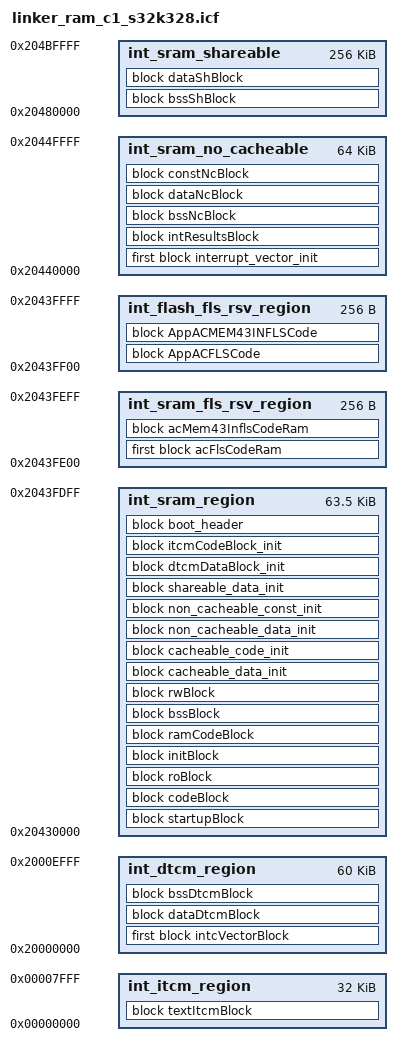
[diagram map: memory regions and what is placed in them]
/*==================================================================================================
*   Project              : RTD AUTOSAR 4.7
*   Platform             : CORTEXM
*   Peripheral           : 
*   Dependencies         : none
*
*   Autosar Version      : 4.7.0
*   Autosar Revision     : ASR_REL_4_7_REV_0000
*   Autosar Conf.Variant :
*   SW Version           : 5.0.0
*   Build Version        : S32K3_RTD_5_0_0_D2408_ASR_REL_4_7_REV_0000_20241002
*
*   Copyright 2020 - 2024 NXP
*
*   NXP Confidential and Proprietary. This software is owned or controlled by NXP and may only be 
*   used strictly in accordance with the applicable license terms.  By expressly 
*   accepting such terms or by downloading, installing, activating and/or otherwise 
*   using the software, you are agreeing that you have read, and that you agree to 
*   comply with and are bound by, such license terms.  If you do not agree to be 
*   bound by the applicable license terms, then you may not retain, install,
*   activate or otherwise use the software.
==================================================================================================*/
/*
* IAR Linker Command File:
* Target device: This linker is demo and it is using for device S32K328 only. It is not part of the production code deliverables.
* Target core: ARM cortex M7
* Linker support for application running on M7_1 core1 only. It need to align with MPU default setup in core_specific.h and system.c as well.
* Memory setting: Local ram of M7_1 (sram)
*/

/*
* IAR Linker Command File:
* 0x00000000    0x00007FFF  32768   ITCM_0
* 0x00000000    0x00007FFF  32768   ITCM_2
* 0x20000000    0x2000FFFF  65536   DTCM_0
* 0x20000000    0x2000FFFF  65536   DTCM_2
* 0x00400000    0x00BFFFFF  8388608 Program Flash
* 0x10000000    0x1001FFFF  131072  Data Flash
* 0x20400000    0x2043FFFF  262144  SRAM_0
* 0x20440000    0x2047FFFF  262144  SRAM_1
* 0x20480000    0x204BFFFF  262144  SRAM_2
* Last 176 KB of CODE_FLASH reserved by HSE Firmware
*/

define symbol int_itcm_start                  = 0x00000000;
define symbol int_itcm_size                   = 0x00008000;    /* 32KB */

define symbol int_dtcm_start                  = 0x20000000;
define symbol int_dtcm_size                   = 0x0000F000;    /* 60KB */

define symbol int_stack_dtcm_start            = 0x2000F000;
define symbol int_stack_dtcm_size             = 0x00001000;     /* 4KB */

define symbol int_sram_c0_start               = 0x20400000;
define symbol int_sram_c0_size                = 0x0001FE00;    /* 128KB. include fls_rsv_c0 */

define symbol int_sram_fls_rsv_c0_start       = 0x2041FE00;
define symbol int_sram_fls_rsv_c0_size        = 0x00000100;    /* 256 byte */

define symbol int_flash_fls_rsv_c0_start      = 0x2041FF00;
define symbol int_flash_fls_rsv_c0_size       = 0x00000100;    /* 256 byte */

define symbol int_sram_no_cacheable_c0_start  = 0x20420000;
define symbol int_sram_no_cacheable_c0_size   = 0x00010000;    /* 64KB, needs to include int_results */

define symbol ram_end_c0                      = 0x20430000;

define symbol int_sram_c1_start               = 0x20430000;
define symbol int_sram_c1_size                = 0x0000FE00;    /* 64KB. include int_sram_fls_rsv_c1 */

define symbol int_sram_fls_rsv_c1_start       = 0x2043FE00;
define symbol int_sram_fls_rsv_c1_size        = 0x00000100;    /* 256 byte for flash access code ram */

define symbol int_flash_fls_rsv_c1_start      = 0x2043FF00;
define symbol int_flash_fls_rsv_c1_size       = 0x00000100;    /* 256 byte for flash access code ram */

define symbol int_sram_no_cacheable_c1_start  = 0x20440000;
define symbol int_sram_no_cacheable_c1_size   = 0x00010000;    /* 64KB, needs to include int_results */

define symbol ram_end_c1                      = 0x20450000;

define symbol int_sram_c2_start               = 0x20450000;
define symbol int_sram_c2_size                = 0x0000FF00;    /* 64KB, include int_sram_fls_rsv_c2 */

define symbol int_sram_fls_rsv_c2_start       = 0x2045FE00;
define symbol int_sram_fls_rsv_c2_size        = 0x00000100;    /* 256 byte for flash access code ram */

define symbol int_flash_fls_rsv_c2_start      = 0x2045FF00;    /* 256 byte for flash access code ram */
define symbol int_flash_fls_rsv_c2_size       = 0x00000100;    /* 256 byte for flash access code ram */

define symbol int_sram_no_cacheable_c2_start  = 0x20460000;
define symbol int_sram_no_cacheable_c2_size   = 0x00020000;    /* 128KB, needs to include int_results  */

define symbol ram_end_c2                      = 0x20480000;

define symbol int_sram_shareable_start        = 0x20480000;
define symbol int_sram_shareable_size         = 0x00040000;    /* 256KB */

define symbol ram_rsvd2                       = 0x204C0000;

define exported symbol __Stack_dtcm_end      = int_stack_dtcm_start;
define exported symbol __Stack_dtcm_start    = int_stack_dtcm_start + int_stack_dtcm_size;

define exported symbol __RAM_INIT                    = 0;
define exported symbol __INT_SRAM_START              = int_sram_c1_start;
define exported symbol __INT_SRAM_END                = ram_end_c1;
define exported symbol __INT_SRAM_SHARE_START        = int_sram_shareable_start;
define exported symbol __INT_SRAM_SHARE_END          = int_sram_shareable_start + int_sram_shareable_size;
define exported symbol __ITCM_INIT                   = 1;
define exported symbol __INT_ITCM_START              = int_itcm_start;
define exported symbol __INT_ITCM_END                = int_itcm_start + int_itcm_size;
define exported symbol __DTCM_INIT                   = 1;
define exported symbol __INT_DTCM_START              = int_dtcm_start;
define exported symbol __INT_DTCM_END                = int_dtcm_start + int_dtcm_size + int_stack_dtcm_size;
define exported symbol __RAM_NO_CACHEABLE_START      = int_sram_no_cacheable_c1_start;

/* Fls module access code support */
define exported symbol int_ac_fls_code_rom_size = 0x80;
define exported symbol int_acmem_43_infls_code_rom_size = 0x80;
define exported symbol int_ac_fls_code_ram_size = 0x80;
define exported symbol int_acmem_43_infls_code_ram_size = 0x80;

define exported symbol Fls_ACEraseRomStart  = int_flash_fls_rsv_c1_start;
define exported symbol Fls_ACEraseRomEnd    = int_flash_fls_rsv_c1_start + int_ac_fls_code_rom_size;
define exported symbol Fls_ACEraseSize      = int_ac_fls_code_rom_size/4; /* Copy 4 bytes at a time*/

define exported symbol Fls_ACWriteRomStart  = int_flash_fls_rsv_c1_start;
define exported symbol Fls_ACWriteRomEnd    = int_flash_fls_rsv_c1_start + int_ac_fls_code_rom_size;
define exported symbol Fls_ACWriteSize      = int_ac_fls_code_rom_size/4; /* Copy 4 bytes at a time*/

define exported symbol _ERASE_FUNC_ADDRESS_ = int_sram_fls_rsv_c1_start;
define exported symbol _WRITE_FUNC_ADDRESS_ = int_sram_fls_rsv_c1_start;

define exported symbol Mem_43_INFLS_ACEraseRomStart  = int_flash_fls_rsv_c1_start + int_ac_fls_code_rom_size;
define exported symbol Mem_43_INFLS_ACEraseRomEnd    = int_flash_fls_rsv_c1_start + int_ac_fls_code_rom_size + int_acmem_43_infls_code_rom_size;
define exported symbol Mem_43_INFLS_ACEraseSize      = int_acmem_43_infls_code_rom_size/4; /* Copy 4 bytes at a time*/ 

define exported symbol Mem_43_INFLS_ACWriteRomStart  = int_flash_fls_rsv_c1_start + int_ac_fls_code_rom_size;
define exported symbol Mem_43_INFLS_ACWriteRomEnd    = int_flash_fls_rsv_c1_start + int_ac_fls_code_rom_size + int_acmem_43_infls_code_rom_size;
define exported symbol Mem_43_INFLS_ACWriteSize      = int_acmem_43_infls_code_rom_size/4; /* Copy 4 bytes at a time*/ 

define exported symbol _MEM_43_INFLS_ERASE_FUNC_ADDRESS_ = int_sram_fls_rsv_c1_start + int_ac_fls_code_ram_size;
define exported symbol _MEM_43_INFLS_WRITE_FUNC_ADDRESS_ = int_sram_fls_rsv_c1_start + int_ac_fls_code_ram_size;

define memory mem with size = 4G;

define region int_sram_region         = mem:[from int_sram_c1_start size int_sram_c1_size];
define region int_sram_no_cacheable   = mem:[from int_sram_no_cacheable_c1_start size int_sram_no_cacheable_c1_size];
define region int_sram_shareable      = mem:[from int_sram_shareable_start size int_sram_shareable_size];
define region int_itcm_region         = mem:[from int_itcm_start size int_itcm_size];
define region int_dtcm_region         = mem:[from int_dtcm_start size int_dtcm_size];
define region int_flash_fls_rsv_region = mem:[from int_flash_fls_rsv_c1_start size int_flash_fls_rsv_c1_size];
define region int_sram_fls_rsv_region  = mem:[from int_sram_fls_rsv_c1_start size int_sram_fls_rsv_c1_size];

initialize manually {
                    section .intvec,
                    section .dtcm_data,
                    section .itcm_text
                    };

do not initialize {
                    section .data,
                    section .mcal_data,
                    section .mcal_data_no_cacheable,
                    section .mcal_shared_data,
                    section .dtcm_data,
                    section .itcm_text,
                    section .bss,
                    section .mcal_bss,
                    section .mcal_bss_no_cacheable,
                    section .mcal_const_no_cacheable,
                    section .mcal_shared_bss,
                    section .dtcm_bss
                  };

/* Internal SRAM */
define block startupBlock with fixed order, alignment = 4                       { section .core_loop, section .startup };
define block codeBlock with fixed order, alignment = 4                          { section .text, section .mcal_text };
define block roBlock with fixed order, alignment = 4                            { section .rodata, section .mcal_const_cfg, section .mcal_const };
define block rwBlock with fixed order, alignment = 4                            { section .data, section .mcal_data};
define block initBlock with fixed order, alignment = 4                          { section .init_table, section .zero_table, section .iar.* };
define block ramCodeBlock with fixed order, alignment = 4                       { section .acmcu_code_rom, section .ramcode};
define block bssBlock with fixed order, alignment = 64                          { section .bss, section .mcal_bss };
define block AppACFLSCode with fixed order, alignment = 4                       { section .acfls_code_rom};
define block AppACMEM43INFLSCode with fixed order, alignment = 4                { section .acmem_43_infls_code_rom};
define block acFlsCodeRam with fixed order, alignment = 4, size = 0x80          { section .acfls_code_ram};
define block acMem43InflsCodeRam with fixed order, alignment = 4, size = 0x80   { section .acmem_43_infls_code_ram};

/* Non cacheable */
define block intResultsBlock with fixed order, alignment = 4, size = 0x100      { section .intresult };
define block bssNcBlock with fixed order, alignment = 4                         { section .mcal_bss_no_cacheable };
define block dataNcBlock with fixed order, alignment = 4                        { section .mcal_data_no_cacheable };
define block constNcBlock with fixed order, alignment = 4                       { section .mcal_const_no_cacheable };

/* Shareable */
define block bssShBlock with fixed order, alignment = 16                        { section .mcal_shared_bss };
define block dataShBlock with fixed order, alignment = 16                       { section .mcal_shared_data };

/* TCM */
define block intcVectorBlock with fixed order, alignment = 2048                 { section .intvec };
define block bssDtcmBlock with fixed order, alignment = 4                       { section .dtcm_bss };
define block dataDtcmBlock with fixed order, alignment = 4                      { section .dtcm_data };
define block textItcmBlock with fixed order, alignment = 4                      { section .itcm_text };
/* Initialized data copy (dummies) */
define block interrupt_vector_init with fixed order, alignment = 2048           { section .intvec_init };
define block cacheable_data_init with fixed order, alignment = 4                { };
define block cacheable_code_init with fixed order, alignment = 4                { };
define block non_cacheable_data_init with fixed order, alignment = 4            { };
define block non_cacheable_const_init with fixed order, alignment = 4           { };
define block shareable_data_init with fixed order, alignment = 4                { };
define block dtcmDataBlock_init with fixed order, alignment = 4                 { section .dtcm_data_init};
define block itcmCodeBlock_init with fixed order, alignment =4                  { section .itcm_text_init};

define block boot_header with fixed order, alignment = 4                        { section .boot_header };

keep { block intResultsBlock, block intcVectorBlock, block interrupt_vector_init};

place in int_sram_region            { block startupBlock, block codeBlock, block roBlock, block initBlock};
place in int_sram_region            { block ramCodeBlock, block bssBlock, block rwBlock};
place in int_sram_region            { block cacheable_data_init, block cacheable_code_init, block non_cacheable_data_init, block non_cacheable_const_init, block shareable_data_init, block dtcmDataBlock_init, block itcmCodeBlock_init, block boot_header };
place in int_dtcm_region            { first block intcVectorBlock, block dataDtcmBlock, block bssDtcmBlock};
place in int_itcm_region            { block textItcmBlock };
place in int_sram_no_cacheable      { first block interrupt_vector_init, block intResultsBlock};
place in int_sram_no_cacheable      { block bssNcBlock };
place in int_sram_no_cacheable      { block dataNcBlock, block constNcBlock};
place in int_sram_shareable         { block bssShBlock};
place in int_sram_shareable         { block dataShBlock};
place in int_flash_fls_rsv_region   { block AppACFLSCode};
place in int_flash_fls_rsv_region   { block AppACMEM43INFLSCode};
place in int_sram_fls_rsv_region    { first block acFlsCodeRam, block acMem43InflsCodeRam};

define exported symbol __ENTRY_VTABLE = start(int_sram_no_cacheable);
/* This values are set, but used only when the core boots from flash */
define exported symbol __CORE0_VTOR = int_sram_no_cacheable_c1_start;
define exported symbol __CORE1_VTOR = int_sram_no_cacheable_c1_start;
define exported symbol __CORE2_VTOR = int_sram_no_cacheable_c1_start;
define exported symbol __CORE3_VTOR = int_sram_no_cacheable_c1_start;
define exported symbol __RAM_INTERRUPT_START = int_dtcm_start;

define exported symbol __ROM_DATA_START = 0x10000000;
define exported symbol __ROM_CODE_START = 0x00400000;
define exported symbol __RAM_SHAREABLE_START = int_sram_shareable_start;
define exported symbol __RAM_SHAREABLE_SIZE = 0x12;  /* 256kbyte in power of 2 */

define exported symbol __RAM_NO_CACHEABLE_SIZE = 0x10;  /* 64kbyte in power of 2 */
define exported symbol __RAM_CACHEABLE_SIZE = 0x10;  /* 64kbyte in power of 2 */

define exported symbol __INDEX_COPY_CORE2 = 0;    /* This symbol is used to initialize data of ITCM/DTCM for CORE2 */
